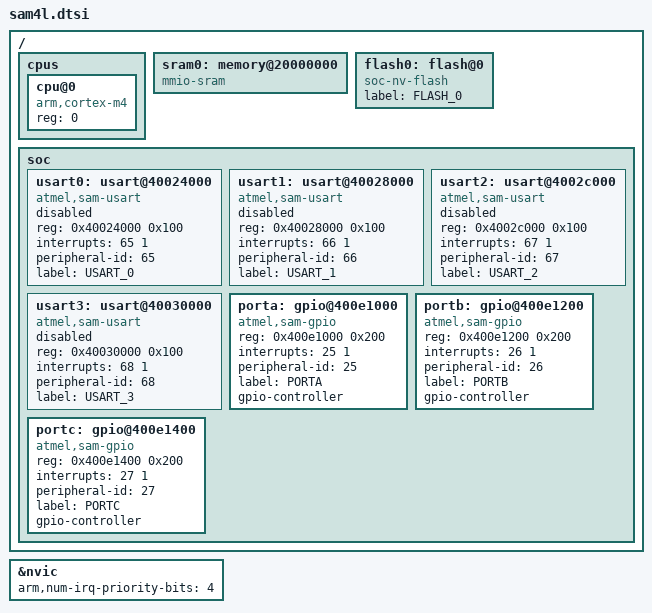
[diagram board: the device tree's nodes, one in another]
/*
 * Copyright (c) 2018 Madani Lainani
 *
 * SPDX-License-Identifier: Apache-2.0
 */

#include <arm/armv7-m.dtsi>
#include <dt-bindings/gpio/gpio.h>

/ {
	cpus {
		#address-cells = <1>;
		#size-cells = <0>;

		cpu@0 {
			device_type = "cpu";
			compatible = "arm,cortex-m4";
			reg = <0>;
		};
	};

	sram0: memory@20000000 {
		device_type = "memory";
		compatible = "mmio-sram";
	};

	flash0: flash@0 {
		compatible = "soc-nv-flash";
		label = "FLASH_0";
	};

	soc {
		usart0: usart@40024000 {
			compatible = "atmel,sam-usart";
			reg = <0x40024000 0x100>;
			interrupts = <65 1>;
			peripheral-id = <65>;
			status = "disabled";
			label = "USART_0";
		};

		usart1: usart@40028000 {
			compatible = "atmel,sam-usart";
			reg = <0x40028000 0x100>;
			interrupts = <66 1>;
			peripheral-id = <66>;
			status = "disabled";
			label = "USART_1";
		};

		usart2: usart@4002c000 {
			compatible = "atmel,sam-usart";
			reg = <0x4002c000 0x100>;
			interrupts = <67 1>;
			peripheral-id = <67>;
			status = "disabled";
			label = "USART_2";
		};

		usart3: usart@40030000 {
			compatible = "atmel,sam-usart";
			reg = <0x40030000 0x100>;
			interrupts = <68 1>;
			peripheral-id = <68>;
			status = "disabled";
			label = "USART_3";
		};

		porta: gpio@400e1000 {
			compatible = "atmel,sam-gpio";
			reg = <0x400e1000 0x200>;
			interrupts = <25 1>;
			peripheral-id = <25>;
			label = "PORTA";
			gpio-controller;
			#gpio-cells = <2>;
		};

		portb: gpio@400e1200 {
			compatible = "atmel,sam-gpio";
			reg = <0x400e1200 0x200>;
			interrupts = <26 1>;
			peripheral-id = <26>;
			label = "PORTB";
			gpio-controller;
			#gpio-cells = <2>;
		};

		portc: gpio@400e1400 {
			compatible = "atmel,sam-gpio";
			reg = <0x400e1400 0x200>;
			interrupts = <27 1>;
			peripheral-id = <27>;
			label = "PORTC";
			gpio-controller;
			#gpio-cells = <2>;
		};

	};
};

&nvic {
	arm,num-irq-priority-bits = <4>;
};
